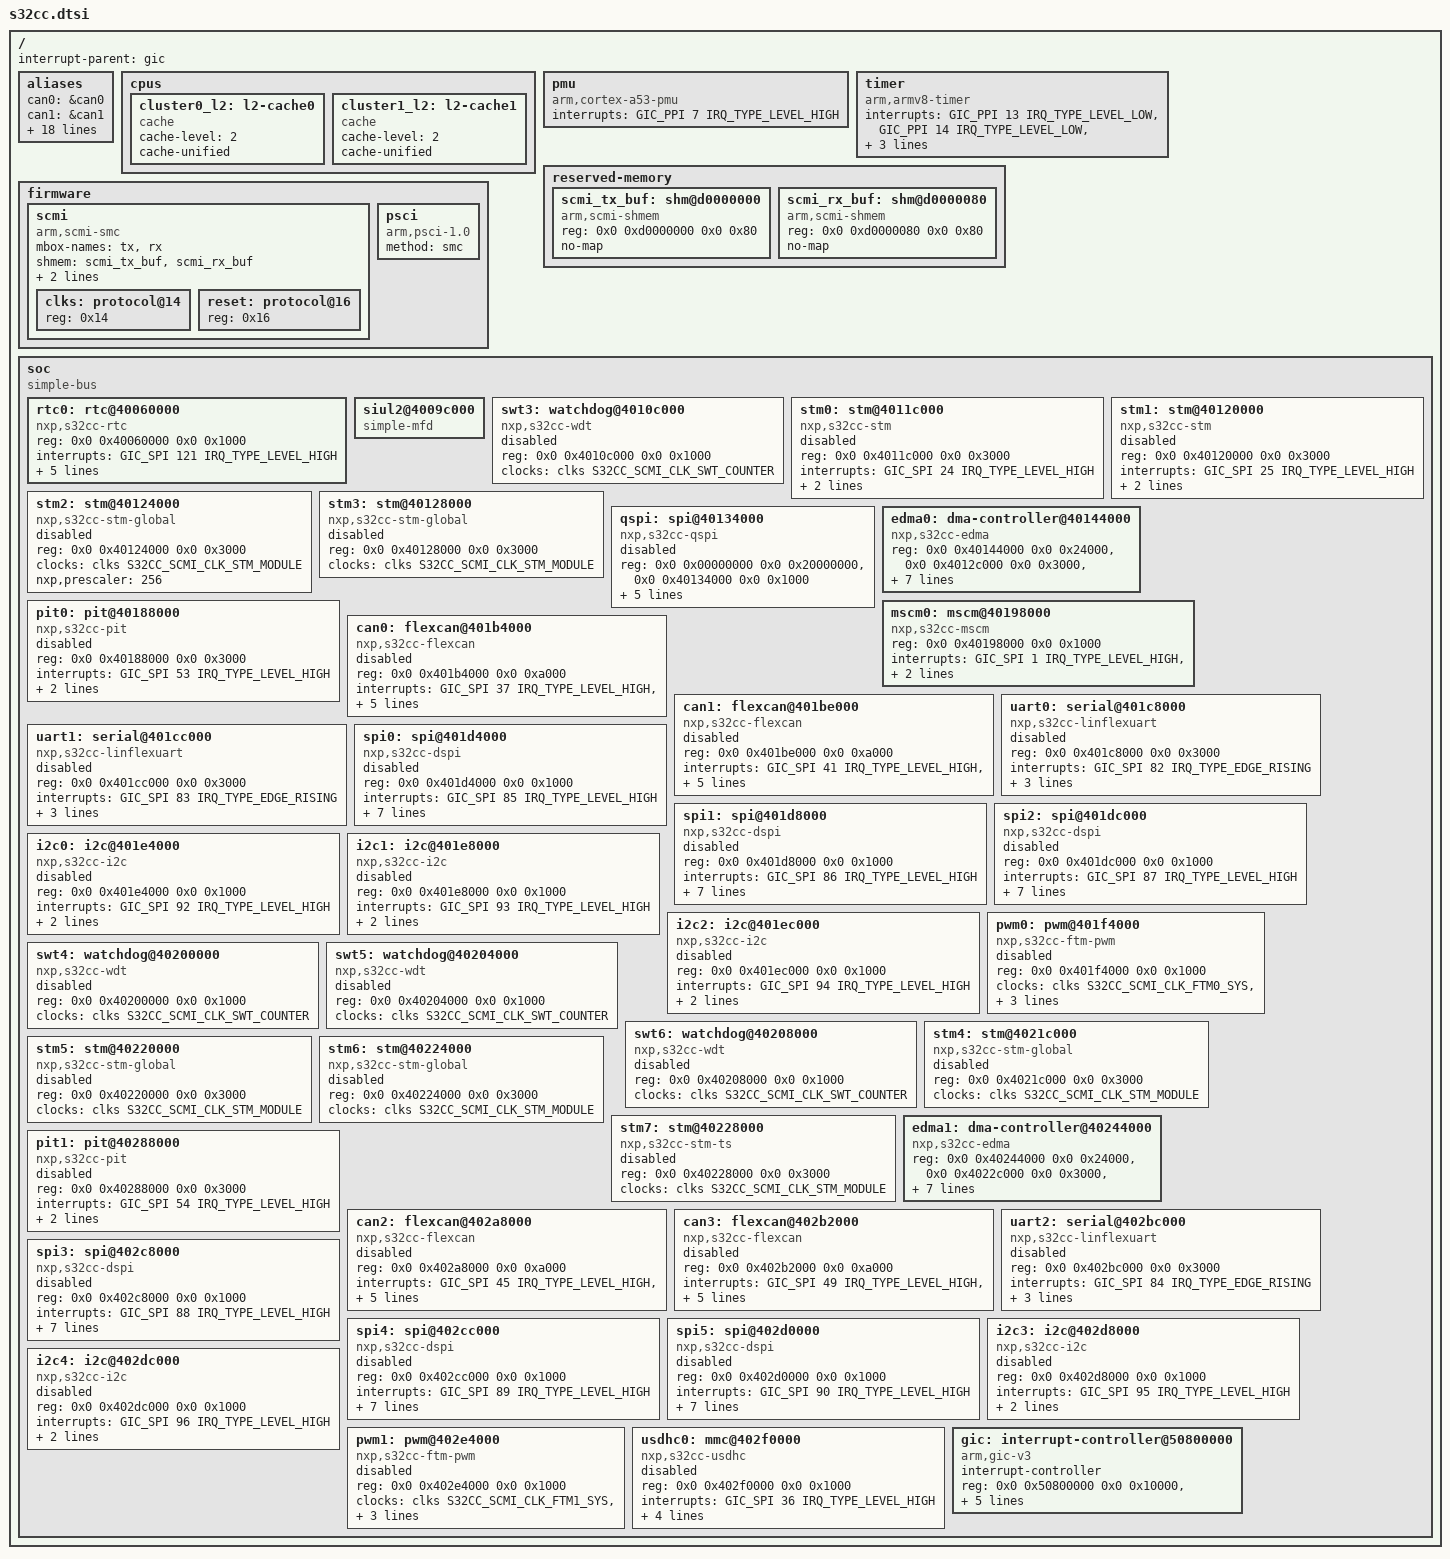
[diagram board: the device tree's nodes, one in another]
// SPDX-License-Identifier: GPL-2.0-or-later OR MIT
/*
 * NXP S32G2 SoC family
 *
 * Copyright (c) 2021 SUSE LLC
 * Copyright 2017-2023 NXP
 */

#include <dt-bindings/interrupt-controller/arm-gic.h>
#include <dt-bindings/clock/s32cc-scmi-clock.h>
#include <dt-bindings/memory/s32cc-siul2.h>
#include <dt-bindings/pinctrl/s32cc-pinfunc.h>
#include <dt-bindings/rtc/s32cc-rtc.h>

/ {
	interrupt-parent = <&gic>;
	#address-cells = <2>;
	#size-cells = <2>;

	aliases {
		can0 = &can0;
		can1 = &can1;
		can2 = &can2;
		can3 = &can3;

		clks = &clks;

		serial0 = &uart0;
		serial1 = &uart1;
		serial2 = &uart2;

		i2c0 = &i2c0;
		i2c1 = &i2c1;
		i2c2 = &i2c2;
		i2c3 = &i2c3;
		i2c4 = &i2c4;

		spi0 = &spi0;
		spi1 = &spi1;
		spi2 = &spi2;
		spi3 = &spi3;
		spi4 = &spi4;
		spi5 = &spi5;
		spi6 = &qspi;
	};

	cpus {
		#address-cells = <1>;
		#size-cells = <0>;

		cluster0_l2: l2-cache0 {
			compatible = "cache";
			cache-level = <2>;
			cache-unified;
			status = "okay";
		};

		cluster1_l2: l2-cache1 {
			compatible = "cache";
			cache-level = <2>;
			cache-unified;
			status = "okay";
		};
	};

	pmu {
		compatible = "arm,cortex-a53-pmu";
		interrupts = <GIC_PPI 7 IRQ_TYPE_LEVEL_HIGH>;
	};

	timer: timer {
		compatible = "arm,armv8-timer";
		interrupts = <GIC_PPI 13 IRQ_TYPE_LEVEL_LOW>,
			     <GIC_PPI 14 IRQ_TYPE_LEVEL_LOW>,
			     <GIC_PPI 11 IRQ_TYPE_LEVEL_LOW>,
			     <GIC_PPI 10 IRQ_TYPE_LEVEL_LOW>;
		clock-frequency = <5000000>;
	};

	reserved-memory  {
		#address-cells = <2>;
		#size-cells = <2>;
		ranges;

		scmi_tx_buf: shm@d0000000 {
			compatible = "arm,scmi-shmem";
			reg = <0x0 0xd0000000 0x0 0x80>;
			no-map;
		};

		scmi_rx_buf: shm@d0000080 {
			compatible = "arm,scmi-shmem";
			reg = <0x0 0xd0000080 0x0 0x80>;
			no-map;
		};
	};

	firmware {
		scmi: scmi {
			compatible = "arm,scmi-smc";
			mbox-names = "tx", "rx";
			shmem = <&scmi_tx_buf>, <&scmi_rx_buf>;
			arm,smc-id = <0xc20000fe>;
			#address-cells = <1>;
			#size-cells = <0>;
			interrupts = <GIC_SPI 300 IRQ_TYPE_EDGE_RISING>;
			interrupt-names = "p2a_notif";
			status = "okay";

			clks: protocol@14 {
				reg = <0x14>;
				#clock-cells = <1>;
			};

			reset: protocol@16 {
				reg = <0x16>;
				#reset-cells = <1>;
			};
		};

		psci {
			compatible = "arm,psci-1.0";
			method = "smc";
		};
	};

	soc {
		compatible = "simple-bus";
		#address-cells = <2>;
		#size-cells = <2>;
		ranges = <0x0 0x0 0x0 0x0 0x0 0x20000000>,
			 <0x0 0x22C00000 0x0 0x22C00000 0x0 0x4000>,
			 <0x0 0x40000000 0x0 0x40000000 0x0 0x14000000>,
			 <0x48 0x0 0x48 0x0 0x8 0x0>,
			 <0x58 0x0 0x58 0x0 0x8 0x0>;

		rtc0: rtc@40060000 {
			compatible = "nxp,s32cc-rtc";
			#interrupt-cells = <3>;
			reg = <0x0 0x40060000 0x0 0x1000>;
			interrupts = <GIC_SPI 121 IRQ_TYPE_LEVEL_HIGH>;	// RTC irq - GIC 153
			clocks = <&clks S32CC_SCMI_CLK_RTC_REG>,
				 <&clks S32CC_SCMI_CLK_RTC_SIRC>,
				 <&clks S32CC_SCMI_CLK_RTC_FIRC>;
			clock-names = "ipg", "sirc", "firc";
			/* Input clock selection: use the 51MHz FIRC with DIV512,
			 * for a roll-over time of just under 13 hours.
			 */
			nxp,clksel = <S32CC_RTC_SOURCE_FIRC>;
			nxp,dividers = <1 0>; // div512 enabled; div32 disabled
		};

		siul2@4009c000 {
			compatible = "simple-mfd";
			#address-cells = <2>;
			#size-cells = <2>;
			status = "okay";

			/* MIDR */
			ranges = <MIDR_SIUL2_0 0x0 0x0 0x4009c000 0x0 0x10>;
		};

		swt3: watchdog@4010c000 {
			compatible = "nxp,s32cc-wdt";
			reg = <0x0 0x4010c000 0x0 0x1000>;
			clocks = <&clks S32CC_SCMI_CLK_SWT_COUNTER>;
			clock-names = "swt";
			status = "disabled";
		};

		stm0: stm@4011c000 {
			compatible = "nxp,s32cc-stm";
			reg = <0x0 0x4011c000 0x0 0x3000>;
			interrupts = <GIC_SPI 24 IRQ_TYPE_LEVEL_HIGH>;
			clocks = <&clks S32CC_SCMI_CLK_STM_MODULE>;
			clock-names = "stm";
			cpu = <2>;
			status = "disabled";
		};

		stm1: stm@40120000 {
			compatible = "nxp,s32cc-stm";
			reg = <0x0 0x40120000 0x0 0x3000>;
			interrupts = <GIC_SPI 25 IRQ_TYPE_LEVEL_HIGH>;
			clocks = <&clks S32CC_SCMI_CLK_STM_MODULE>;
			clock-names = "stm";
			cpu = <3>;
			status = "disabled";
		};

		stm2: stm@40124000 {
			compatible = "nxp,s32cc-stm-global";
			reg = <0x0 0x40124000 0x0 0x3000>;
			clocks = <&clks S32CC_SCMI_CLK_STM_MODULE>;
			clock-names = "stm";
			nxp,prescaler = <256>;
			status = "disabled";
		};

		stm3: stm@40128000 {
			compatible = "nxp,s32cc-stm-global";
			reg = <0x0 0x40128000 0x0 0x3000>;
			clocks = <&clks S32CC_SCMI_CLK_STM_MODULE>;
			clock-names = "stm";
			status = "disabled";
		};

		qspi: spi@40134000 {
			compatible = "nxp,s32cc-qspi";
			#address-cells = <1>;
			#size-cells = <0>;
			reg = <0x0 0x00000000 0x0 0x20000000>,
				<0x0 0x40134000 0x0 0x1000>;
			reg-names = "QuadSPI-memory", "QuadSPI";
			interrupts = <GIC_SPI 32 IRQ_TYPE_LEVEL_HIGH>;
			clock-names = "qspi_en", "qspi";
			clocks = <&clks S32CC_SCMI_CLK_QUADSPI_FLASH1X>,
				 <&clks S32CC_SCMI_CLK_QUADSPI_FLASH1X>;
			spi-max-frequency = <200000000>;
			spi-num-chipselects = <2>;
			status = "disabled";
		};

		edma0: dma-controller@40144000 {
			#dma-cells = <2>;
			compatible = "nxp,s32cc-edma";
			reg = <0x0 0x40144000 0x0 0x24000>,
			      <0x0 0x4012c000 0x0 0x3000>,
			      <0x0 0x40130000 0x0 0x3000>;
			dma-channels = <32>;
			interrupts = <GIC_SPI 8 IRQ_TYPE_LEVEL_HIGH>,
				     <GIC_SPI 9 IRQ_TYPE_LEVEL_HIGH>,
				     <GIC_SPI 10 IRQ_TYPE_LEVEL_HIGH>;
			interrupt-names = "edma-tx_0-15",
					  "edma-tx_16-31",
					  "edma-err";
			clock-names = "dmamux0", "dmamux1";
			clocks = <&clks S32CC_SCMI_CLK_EDMA_MODULE>,
				 <&clks S32CC_SCMI_CLK_EDMA_AHB>;
			status = "okay";
		};

		pit0: pit@40188000 {
			compatible = "nxp,s32cc-pit";
			reg = <0x0 0x40188000 0x0 0x3000>;
			interrupts = <GIC_SPI 53 IRQ_TYPE_LEVEL_HIGH>;
			clocks = <&clks S32CC_SCMI_CLK_PIT_MODULE>;
			clock-names = "pit";
			cpu = <0>;
			status = "disabled";
		};

		mscm0: mscm@40198000 {
			compatible = "nxp,s32cc-mscm";
			reg = <0x0 0x40198000 0x0 0x1000>;
			/* CPU2CPU interrupts */
			interrupts = <GIC_SPI 1 IRQ_TYPE_LEVEL_HIGH>, // CPU to M7/A53 interrupt#0
				     <GIC_SPI 2 IRQ_TYPE_LEVEL_HIGH>, // CPU to M7/A53 interrupt#1
				     <GIC_SPI 3 IRQ_TYPE_LEVEL_HIGH>; // CPU to M7/A53 interrupt#2
		};

		can0: flexcan@401b4000 {
			compatible = "nxp,s32cc-flexcan";
			reg = <0x0 0x401b4000 0x0 0xa000>;
			interrupts = <GIC_SPI 37 IRQ_TYPE_LEVEL_HIGH>,
				     <GIC_SPI 38 IRQ_TYPE_LEVEL_HIGH>,
				     <GIC_SPI 39 IRQ_TYPE_LEVEL_HIGH>,
				     <GIC_SPI 40 IRQ_TYPE_LEVEL_HIGH>;
			interrupt-names = "state", "berr", "mb_0-7", "mb_8-127";
			clocks = <&clks S32CC_SCMI_CLK_FLEXCAN_REG>,
				 <&clks S32CC_SCMI_CLK_FLEXCAN_CAN>;
			clock-names = "ipg", "per";
			status = "disabled";
		};

		can1: flexcan@401be000 {
			compatible = "nxp,s32cc-flexcan";
			reg = <0x0 0x401be000 0x0 0xa000>;
			interrupts = <GIC_SPI 41 IRQ_TYPE_LEVEL_HIGH>,
				     <GIC_SPI 42 IRQ_TYPE_LEVEL_HIGH>,
				     <GIC_SPI 43 IRQ_TYPE_LEVEL_HIGH>,
				     <GIC_SPI 44 IRQ_TYPE_LEVEL_HIGH>;
			interrupt-names = "state", "berr", "mb_0-7", "mb_8-127";
			clocks = <&clks S32CC_SCMI_CLK_FLEXCAN_REG>,
				 <&clks S32CC_SCMI_CLK_FLEXCAN_CAN>;
			clock-names = "ipg", "per";
			status = "disabled";
		};

		uart0: serial@401c8000 {
			compatible = "nxp,s32cc-linflexuart",
				     "fsl,s32v234-linflexuart";
			reg = <0x0 0x401c8000 0x0 0x3000>;
			interrupts = <GIC_SPI 82 IRQ_TYPE_EDGE_RISING>;
			clocks = <&clks S32CC_SCMI_CLK_LINFLEX_LIN>,
				 <&clks S32CC_SCMI_CLK_LINFLEX_XBAR>;
			clock-names = "lin", "ipg";
			dmas = <&edma0 0 4>,
			       <&edma0 0 3>;
			dma-names = "rx", "tx";
			status = "disabled";
		};

		uart1: serial@401cc000 {
			compatible = "nxp,s32cc-linflexuart",
				     "fsl,s32v234-linflexuart";
			reg = <0x0 0x401cc000 0x0 0x3000>;
			interrupts = <GIC_SPI 83 IRQ_TYPE_EDGE_RISING>;
			clocks = <&clks S32CC_SCMI_CLK_LINFLEX_LIN>,
				 <&clks S32CC_SCMI_CLK_LINFLEX_XBAR>;
			clock-names = "lin", "ipg";
			dmas = <&edma0 0 6>,
			       <&edma0 0 5>;
			dma-names = "rx", "tx";
			status = "disabled";
		};

		spi0: spi@401d4000 {
			compatible = "nxp,s32cc-dspi";
			reg = <0x0 0x401d4000 0x0 0x1000>;
			interrupts = <GIC_SPI 85 IRQ_TYPE_LEVEL_HIGH>;
			clocks = <&clks S32CC_SCMI_CLK_SPI_MODULE>;
			clock-names = "dspi";
			spi-num-chipselects = <8>;
			bus-num = <0>;
			spi-fifo-size = <5>;
			spi-cpol;
			spi-cpha;
			dmas = <&edma0 0 7>, <&edma0 0 8>;
			dma-names = "tx", "rx";
			status = "disabled";
		};

		spi1: spi@401d8000 {
			compatible = "nxp,s32cc-dspi";
			reg = <0x0 0x401d8000 0x0 0x1000>;
			interrupts = <GIC_SPI 86 IRQ_TYPE_LEVEL_HIGH>;
			clocks = <&clks S32CC_SCMI_CLK_SPI_MODULE>;
			clock-names = "dspi";
			spi-num-chipselects = <5>;
			bus-num = <1>;
			spi-fifo-size = <5>;
			spi-cpol;
			spi-cpha;
			dmas = <&edma0 0 10>, <&edma0 0 11>;
			dma-names = "tx", "rx";
			status = "disabled";
		};

		spi2: spi@401dc000 {
			compatible = "nxp,s32cc-dspi";
			reg = <0x0 0x401dc000 0x0 0x1000>;
			interrupts = <GIC_SPI 87 IRQ_TYPE_LEVEL_HIGH>;
			clocks = <&clks S32CC_SCMI_CLK_SPI_MODULE>;
			clock-names = "dspi";
			spi-num-chipselects = <5>;
			bus-num = <2>;
			spi-fifo-size = <5>;
			spi-cpol;
			spi-cpha;
			dmas = <&edma0 0 13>, <&edma0 0 14>;
			dma-names = "tx", "rx";
			status = "disabled";
		};

		i2c0: i2c@401e4000 {
			compatible = "nxp,s32cc-i2c";
			reg = <0x0 0x401e4000 0x0 0x1000>;
			interrupts = <GIC_SPI 92 IRQ_TYPE_LEVEL_HIGH>;
			clocks = <&clks S32CC_SCMI_CLK_I2C_REG>;
			clock-names = "ipg";
			dmas = <&edma0 0 16>,
			       <&edma0 0 17>;
			dma-names = "rx","tx";
			#address-cells = <1>;
			#size-cells = <0>;
			status = "disabled";
		};

		i2c1: i2c@401e8000 {
			compatible = "nxp,s32cc-i2c";
			reg = <0x0 0x401e8000 0x0 0x1000>;
			interrupts = <GIC_SPI 93 IRQ_TYPE_LEVEL_HIGH>;
			clocks = <&clks S32CC_SCMI_CLK_I2C_REG>;
			clock-names = "ipg";
			dmas = <&edma0 0 18>,
			       <&edma0 0 19>;
			dma-names = "rx","tx";
			#address-cells = <1>;
			#size-cells = <0>;
			status = "disabled";
		};

		i2c2: i2c@401ec000 {
			compatible = "nxp,s32cc-i2c";
			reg = <0x0 0x401ec000 0x0 0x1000>;
			interrupts = <GIC_SPI 94 IRQ_TYPE_LEVEL_HIGH>;
			clocks = <&clks S32CC_SCMI_CLK_I2C_REG>;
			clock-names = "ipg";
			dmas = <&edma1 1 16>,
			       <&edma1 1 17>;
			dma-names = "rx","tx";
			#address-cells = <1>;
			#size-cells = <0>;
			status = "disabled";
		};

		pwm0: pwm@401f4000 {
			compatible = "nxp,s32cc-ftm-pwm";
			#pwm-cells = <3>;
			reg = <0x0 0x401f4000 0x0 0x1000>;
			clock-names = "ftm_sys", "ftm_ext",
					  "ftm_fix", "ftm_cnt_clk_en";
			clocks = <&clks S32CC_SCMI_CLK_FTM0_SYS>,
				 <&clks S32CC_SCMI_CLK_FTM0_EXT>,
				 <&clks S32CC_SCMI_CLK_FTM0_SYS>,
				 <&clks S32CC_SCMI_CLK_FTM0_SYS>;
			status = "disabled";
		};

		swt4: watchdog@40200000 {
			compatible = "nxp,s32cc-wdt";
			reg = <0x0 0x40200000 0x0 0x1000>;
			clocks = <&clks S32CC_SCMI_CLK_SWT_COUNTER>;
			clock-names = "swt";
			status = "disabled";
		};

		swt5: watchdog@40204000 {
			compatible = "nxp,s32cc-wdt";
			reg = <0x0 0x40204000 0x0 0x1000>;
			clocks = <&clks S32CC_SCMI_CLK_SWT_COUNTER>;
			clock-names = "swt";
			status = "disabled";
		};

		swt6: watchdog@40208000 {
			compatible = "nxp,s32cc-wdt";
			reg = <0x0 0x40208000 0x0 0x1000>;
			clocks = <&clks S32CC_SCMI_CLK_SWT_COUNTER>;
			clock-names = "swt";
			status = "disabled";
		};

		stm4: stm@4021c000 {
			compatible = "nxp,s32cc-stm-global";
			reg = <0x0 0x4021c000 0x0 0x3000>;
			clocks = <&clks S32CC_SCMI_CLK_STM_MODULE>;
			clock-names = "stm";
			status = "disabled";
		};

		stm5: stm@40220000 {
			compatible = "nxp,s32cc-stm-global";
			reg = <0x0 0x40220000 0x0 0x3000>;
			clocks = <&clks S32CC_SCMI_CLK_STM_MODULE>;
			clock-names = "stm";
			status = "disabled";
		};

		stm6: stm@40224000 {
			compatible = "nxp,s32cc-stm-global";
			reg = <0x0 0x40224000 0x0 0x3000>;
			clocks = <&clks S32CC_SCMI_CLK_STM_MODULE>;
			clock-names = "stm";
			status = "disabled";
		};

		stm7: stm@40228000 {
			compatible = "nxp,s32cc-stm-ts";
			reg = <0x0 0x40228000 0x0 0x3000>;
			clocks = <&clks S32CC_SCMI_CLK_STM_MODULE>;
			clock-names = "stm";
			status = "disabled";
		};

		edma1: dma-controller@40244000 {
			#dma-cells = <2>;
			compatible = "nxp,s32cc-edma";
			reg = <0x0 0x40244000 0x0 0x24000>,
			      <0x0 0x4022c000 0x0 0x3000>,
			      <0x0 0x40230000 0x0 0x3000>;
			dma-channels = <32>;
			interrupts = <GIC_SPI 11 IRQ_TYPE_LEVEL_HIGH>,
				     <GIC_SPI 12 IRQ_TYPE_LEVEL_HIGH>,
				     <GIC_SPI 13 IRQ_TYPE_LEVEL_HIGH>;
			interrupt-names = "edma-tx_0-15",
					  "edma-tx_16-31",
					  "edma-err";
			clock-names = "dmamux0", "dmamux1";
			clocks = <&clks S32CC_SCMI_CLK_EDMA_MODULE>,
				 <&clks S32CC_SCMI_CLK_EDMA_AHB>;
			status = "okay";
		};

		pit1: pit@40288000 {
			compatible = "nxp,s32cc-pit";
			reg = <0x0 0x40288000 0x0 0x3000>;
			interrupts = <GIC_SPI 54 IRQ_TYPE_LEVEL_HIGH>;
			clocks = <&clks S32CC_SCMI_CLK_PIT_MODULE>;
			clock-names = "pit";
			cpu = <1>;
			status = "disabled";
		};

		can2: flexcan@402a8000 {
			compatible = "nxp,s32cc-flexcan";
			reg = <0x0 0x402a8000 0x0 0xa000>;
			interrupts = <GIC_SPI 45 IRQ_TYPE_LEVEL_HIGH>,
				     <GIC_SPI 46 IRQ_TYPE_LEVEL_HIGH>,
				     <GIC_SPI 47 IRQ_TYPE_LEVEL_HIGH>,
				     <GIC_SPI 48 IRQ_TYPE_LEVEL_HIGH>;
			interrupt-names = "state", "berr", "mb_0-7", "mb_8-127";
			clocks = <&clks S32CC_SCMI_CLK_FLEXCAN_REG>,
				 <&clks S32CC_SCMI_CLK_FLEXCAN_CAN>;
			clock-names = "ipg", "per";
			status = "disabled";
		};

		can3: flexcan@402b2000 {
			compatible = "nxp,s32cc-flexcan";
			reg = <0x0 0x402b2000 0x0 0xa000>;
			interrupts = <GIC_SPI 49 IRQ_TYPE_LEVEL_HIGH>,
				     <GIC_SPI 50 IRQ_TYPE_LEVEL_HIGH>,
				     <GIC_SPI 51 IRQ_TYPE_LEVEL_HIGH>,
				     <GIC_SPI 52 IRQ_TYPE_LEVEL_HIGH>;
			interrupt-names = "state", "berr", "mb_0-7", "mb_8-127";
			clocks = <&clks S32CC_SCMI_CLK_FLEXCAN_REG>,
				 <&clks S32CC_SCMI_CLK_FLEXCAN_CAN>;
			clock-names = "ipg", "per";
			status = "disabled";
		};

		uart2: serial@402bc000 {
			compatible = "nxp,s32cc-linflexuart",
				     "fsl,s32v234-linflexuart";
			reg = <0x0 0x402bc000 0x0 0x3000>;
			interrupts = <GIC_SPI 84 IRQ_TYPE_EDGE_RISING>;
			clocks = <&clks S32CC_SCMI_CLK_LINFLEX_LIN>,
				 <&clks S32CC_SCMI_CLK_LINFLEX_XBAR>;
			clock-names = "lin", "ipg";
			dmas = <&edma1 1 4>,
			       <&edma1 1 3>;
			dma-names = "rx", "tx";
			status = "disabled";
		};

		spi3: spi@402c8000 {
			compatible = "nxp,s32cc-dspi";
			reg = <0x0 0x402c8000 0x0 0x1000>;
			interrupts = <GIC_SPI 88 IRQ_TYPE_LEVEL_HIGH>;
			clocks = <&clks S32CC_SCMI_CLK_SPI_MODULE>;
			clock-names = "dspi";
			spi-num-chipselects = <5>;
			bus-num = <3>;
			spi-fifo-size = <5>;
			spi-cpol;
			spi-cpha;
			dmas = <&edma0 1 7>, <&edma0 1 8>;
			dma-names = "tx", "rx";
			status = "disabled";
		};

		spi4: spi@402cc000 {
			compatible = "nxp,s32cc-dspi";
			reg = <0x0 0x402cc000 0x0 0x1000>;
			interrupts = <GIC_SPI 89 IRQ_TYPE_LEVEL_HIGH>;
			clocks = <&clks S32CC_SCMI_CLK_SPI_MODULE>;
			clock-names = "dspi";
			spi-num-chipselects = <5>;
			bus-num = <4>;
			spi-fifo-size = <5>;
			spi-cpol;
			spi-cpha;
			dmas = <&edma0 1 10>, <&edma0 1 11>;
			dma-names = "tx", "rx";
			status = "disabled";
		};

		spi5: spi@402d0000 {
			compatible = "nxp,s32cc-dspi";
			reg = <0x0 0x402d0000 0x0 0x1000>;
			interrupts = <GIC_SPI 90 IRQ_TYPE_LEVEL_HIGH>;
			clocks = <&clks S32CC_SCMI_CLK_SPI_MODULE>;
			clock-names = "dspi";
			spi-num-chipselects = <5>;
			bus-num = <5>;
			spi-fifo-size = <5>;
			spi-cpol;
			spi-cpha;
			dmas = <&edma0 1 13>, <&edma0 1 14>;
			dma-names = "tx", "rx";
			status = "disabled";
		};

		i2c3: i2c@402d8000 {
			compatible = "nxp,s32cc-i2c";
			reg = <0x0 0x402d8000 0x0 0x1000>;
			interrupts = <GIC_SPI 95 IRQ_TYPE_LEVEL_HIGH>;
			clocks = <&clks S32CC_SCMI_CLK_I2C_REG>;
			clock-names = "ipg";
			dmas = <&edma1 1 18>,
			       <&edma1 1 19>;
			dma-names = "rx","tx";
			#address-cells = <1>;
			#size-cells = <0>;
			status = "disabled";
		};

		i2c4: i2c@402dc000 {
			compatible = "nxp,s32cc-i2c";
			reg = <0x0 0x402dc000 0x0 0x1000>;
			interrupts = <GIC_SPI 96 IRQ_TYPE_LEVEL_HIGH>;
			clocks = <&clks S32CC_SCMI_CLK_I2C_REG>;
			clock-names = "ipg";
			dmas = <&edma1 1 20>,
			       <&edma1 1 21>;
			dma-names = "rx","tx";
			#address-cells = <1>;
			#size-cells = <0>;
			status = "disabled";
		};

		pwm1: pwm@402e4000 {
			compatible = "nxp,s32cc-ftm-pwm";
			#pwm-cells = <3>;
			reg = <0x0 0x402e4000 0x0 0x1000>;
			clock-names = "ftm_sys", "ftm_ext",
				      "ftm_fix", "ftm_cnt_clk_en";
			clocks = <&clks S32CC_SCMI_CLK_FTM1_SYS>,
				 <&clks S32CC_SCMI_CLK_FTM1_EXT>,
				 <&clks S32CC_SCMI_CLK_FTM1_SYS>,
				 <&clks S32CC_SCMI_CLK_FTM1_SYS>;
			status = "disabled";
		};

		usdhc0: mmc@402f0000 {
			compatible = "nxp,s32cc-usdhc";
			reg = <0x0 0x402f0000 0x0 0x1000>;
			interrupts = <GIC_SPI 36 IRQ_TYPE_LEVEL_HIGH>;
			clocks = <&clks S32CC_SCMI_CLK_USDHC_MODULE>,
				 <&clks S32CC_SCMI_CLK_USDHC_AHB>,
				 <&clks S32CC_SCMI_CLK_USDHC_CORE>;
			clock-names = "ipg", "ahb", "per";
			bus-width = <8>;
			status = "disabled";
		};

		gic: interrupt-controller@50800000 {
			compatible = "arm,gic-v3";
			#interrupt-cells = <3>;
			#address-cells = <2>;
			#size-cells = <2>;
			interrupt-controller;
			reg = <0x0 0x50800000 0x0 0x10000>,
			      <0x0 0x50880000 0x0 0x80000>,
			      <0x0 0x50400000 0x0 0x2000>,
			      <0x0 0x50410000 0x0 0x2000>,
			      <0x0 0x50420000 0x0 0x2000>;
			interrupts = <GIC_PPI 9 IRQ_TYPE_LEVEL_HIGH>;
		};
	};
};
